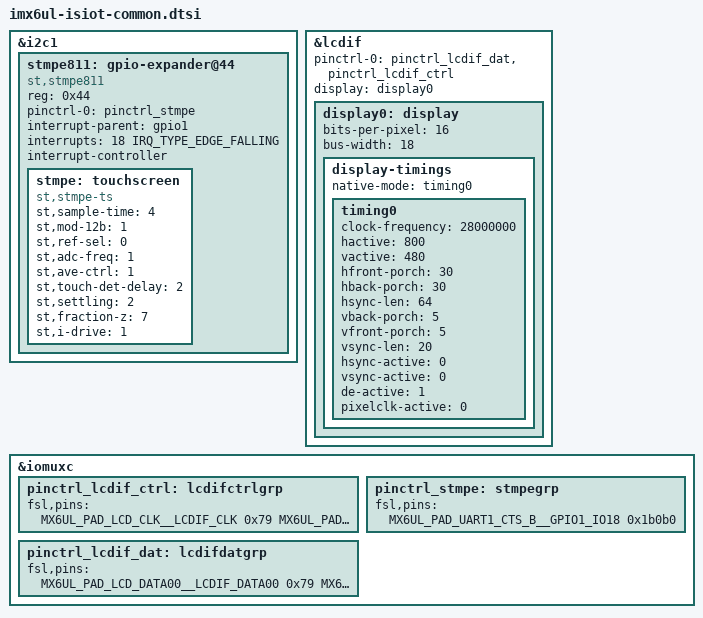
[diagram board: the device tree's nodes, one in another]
/*
 * Copyright (C) 2016 Amarula Solutions B.V.
 * Copyright (C) 2016 Engicam S.r.l.
 *
 * This file is dual-licensed: you can use it either under the terms
 * of the GPL or the X11 license, at your option. Note that this dual
 * licensing only applies to this file, and not this project as a
 * whole.
 *
 *  a) This file is free software; you can redistribute it and/or
 *     modify it under the terms of the GNU General Public License
 *     version 2 as published by the Free Software Foundation.
 *
 *     This file is distributed in the hope that it will be useful,
 *     but WITHOUT ANY WARRANTY; without even the implied warranty of
 *     MERCHANTABILITY or FITNESS FOR A PARTICULAR PURPOSE.  See the
 *     GNU General Public License for more details.
 *
 * Or, alternatively,
 *
 *  b) Permission is hereby granted, free of charge, to any person
 *     obtaining a copy of this software and associated documentation
 *     files (the "Software"), to deal in the Software without
 *     restriction, including without limitation the rights to use,
 *     copy, modify, merge, publish, distribute, sublicense, and/or
 *     sell copies of the Software, and to permit persons to whom the
 *     Software is furnished to do so, subject to the following
 *     conditions:
 *
 *     The above copyright notice and this permission notice shall be
 *     included in all copies or substantial portions of the Software.
 *
 *     THE SOFTWARE IS PROVIDED "AS IS", WITHOUT WARRANTY OF ANY KIND,
 *     EXPRESS OR IMPLIED, INCLUDING BUT NOT LIMITED TO THE WARRANTIES
 *     OF MERCHANTABILITY, FITNESS FOR A PARTICULAR PURPOSE AND
 *     NONINFRINGEMENT. IN NO EVENT SHALL THE AUTHORS OR COPYRIGHT
 *     HOLDERS BE LIABLE FOR ANY CLAIM, DAMAGES OR OTHER LIABILITY,
 *     WHETHER IN AN ACTION OF CONTRACT, TORT OR OTHERWISE, ARISING
 *     FROM, OUT OF OR IN CONNECTION WITH THE SOFTWARE OR THE USE OR
 *     OTHER DEALINGS IN THE SOFTWARE.
 */

&i2c1 {
	stmpe811: gpio-expander@44 {
		compatible = "st,stmpe811";
		reg = <0x44>;
		#address-cells = <1>;
		#size-cells = <0>;
		pinctrl-names = "default";
		pinctrl-0 = <&pinctrl_stmpe>;
		interrupt-parent = <&gpio1>;
		interrupts = <18 IRQ_TYPE_EDGE_FALLING>;
		interrupt-controller;
		#interrupt-cells = <2>;

		stmpe: touchscreen {
			compatible = "st,stmpe-ts";
			st,sample-time = <4>;
			st,mod-12b = <1>;
			st,ref-sel = <0>;
			st,adc-freq = <1>;
			st,ave-ctrl = <1>;
			st,touch-det-delay = <2>;
			st,settling = <2>;
			st,fraction-z = <7>;
			st,i-drive = <1>;
		};
	};
};

&lcdif {
	pinctrl-names = "default";
	pinctrl-0 = <&pinctrl_lcdif_dat
		     &pinctrl_lcdif_ctrl>;
	display = <&display0>;
	status = "okay";

	display0: display {
		bits-per-pixel = <16>;
		bus-width = <18>;

		display-timings {
			native-mode = <&timing0>;
			timing0: timing0 {
				clock-frequency = <28000000>;
				hactive = <800>;
				vactive = <480>;
				hfront-porch = <30>;
				hback-porch = <30>;
				hsync-len = <64>;
				vback-porch = <5>;
				vfront-porch = <5>;
				vsync-len = <20>;
				hsync-active = <0>;
				vsync-active = <0>;
				de-active = <1>;
				pixelclk-active = <0>;
			};
		};
	};
};

&iomuxc {
	pinctrl_lcdif_ctrl: lcdifctrlgrp {
		fsl,pins = <
			MX6UL_PAD_LCD_CLK__LCDIF_CLK	    0x79
			MX6UL_PAD_LCD_ENABLE__LCDIF_ENABLE  0x79
			MX6UL_PAD_LCD_HSYNC__LCDIF_HSYNC    0x79
			MX6UL_PAD_LCD_VSYNC__LCDIF_VSYNC    0x79
		>;
	};

	pinctrl_lcdif_dat: lcdifdatgrp {
		fsl,pins = <
			MX6UL_PAD_LCD_DATA00__LCDIF_DATA00  0x79
			MX6UL_PAD_LCD_DATA01__LCDIF_DATA01  0x79
			MX6UL_PAD_LCD_DATA02__LCDIF_DATA02  0x79
			MX6UL_PAD_LCD_DATA03__LCDIF_DATA03  0x79
			MX6UL_PAD_LCD_DATA04__LCDIF_DATA04  0x79
			MX6UL_PAD_LCD_DATA05__LCDIF_DATA05  0x79
			MX6UL_PAD_LCD_DATA06__LCDIF_DATA06  0x79
			MX6UL_PAD_LCD_DATA07__LCDIF_DATA07  0x79
			MX6UL_PAD_LCD_DATA08__LCDIF_DATA08  0x79
			MX6UL_PAD_LCD_DATA09__LCDIF_DATA09  0x79
			MX6UL_PAD_LCD_DATA10__LCDIF_DATA10  0x79
			MX6UL_PAD_LCD_DATA11__LCDIF_DATA11  0x79
			MX6UL_PAD_LCD_DATA12__LCDIF_DATA12  0x79
			MX6UL_PAD_LCD_DATA13__LCDIF_DATA13  0x79
			MX6UL_PAD_LCD_DATA14__LCDIF_DATA14  0x79
			MX6UL_PAD_LCD_DATA15__LCDIF_DATA15  0x79
			MX6UL_PAD_LCD_DATA16__LCDIF_DATA16  0x79
			MX6UL_PAD_LCD_DATA17__LCDIF_DATA17  0x79
		>;
	};

	pinctrl_stmpe: stmpegrp  {
		fsl,pins = <
			MX6UL_PAD_UART1_CTS_B__GPIO1_IO18 0x1b0b0
		>;
	};
};
